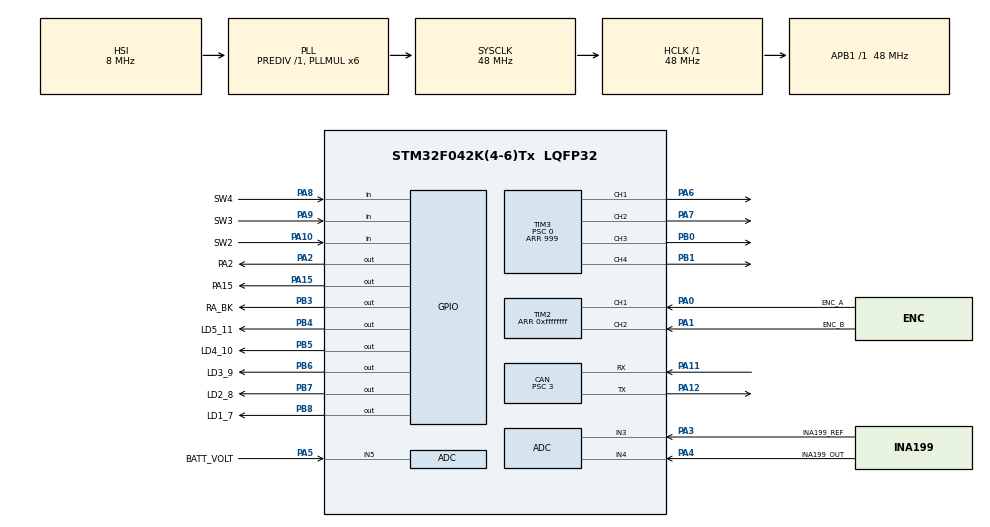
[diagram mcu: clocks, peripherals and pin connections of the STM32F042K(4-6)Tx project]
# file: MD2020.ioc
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ADC.ContinuousConvMode=ENABLE
ADC.DMAContinuousRequests=ENABLE
ADC.EOCSelection=ADC_EOC_SINGLE_CONV
CAN.BS1=CAN_BS1_13TQ
CAN.BS2=CAN_BS2_2TQ
CAN.CalculateTimeQuantum=62.5
CAN.Prescaler=3
CAN.SJW=CAN_SJW_1TQ
Dma.ADC.0.Direction=DMA_PERIPH_TO_MEMORY
Dma.ADC.0.Instance=DMA1_Channel1
Dma.ADC.0.MemDataAlignment=DMA_MDATAALIGN_HALFWORD
Dma.ADC.0.MemInc=DMA_MINC_ENABLE
Dma.ADC.0.Mode=DMA_CIRCULAR
Dma.ADC.0.PeriphDataAlignment=DMA_PDATAALIGN_HALFWORD
Dma.ADC.0.PeriphInc=DMA_PINC_DISABLE
Dma.ADC.0.Priority=DMA_PRIORITY_LOW
Dma.Request0=ADC
FREERTOS.INCLUDE_uxTaskPriorityGet=0
FREERTOS.INCLUDE_vTaskDelayUntil=1
FREERTOS.INCLUDE_vTaskDelete=0
FREERTOS.INCLUDE_vTaskPrioritySet=1
FREERTOS.INCLUDE_vTaskSuspend=0
FREERTOS.MEMORY_ALLOCATION=1
FREERTOS.Tasks01=defaultTask,0,100,StartDefaultTask,Default,NULL,Static,defaultTaskBuffer,defaultTaskControlBlock;Control,3,100,StartControl,Default,NULL,Static,myTask02Buffer,myTask02ControlBlock
FREERTOS.configMAX_TASK_NAME_LEN=12
FREERTOS.configMINIMAL_STACK_SIZE=100
FREERTOS.configTOTAL_HEAP_SIZE=1024
Mcu.Family=STM32F0
Mcu.Name=STM32F042K(4-6)Tx
Mcu.Package=LQFP32
NVIC.DMA1_Channel1_IRQn=true\:3\:0\:false\:false\:true\:true\:false\:true
NVIC.TIM17_IRQn=true\:0\:0\:false\:false\:true\:false\:false\:true
NVIC.TIM3_IRQn=true\:3\:0\:false\:false\:true\:true\:true\:true
NVIC.TimeBase=TIM17_IRQn
NVIC.TimeBaseIP=TIM17
PA0.GPIO_Label=ENC_A
PA0.Signal=S_TIM2_CH1_ETR
PA1.GPIO_Label=ENC_B
PA1.Signal=S_TIM2_CH2
PA10.GPIO_Label=SW2
PA10.GPIO_PuPd=GPIO_PULLUP
PA10.Signal=GPIO_Input
PA11.Mode=Master
PA11.Signal=CAN_RX
PA12.Mode=Master
PA12.Signal=CAN_TX
PA13.Mode=Serial_Wire
PA13.Signal=SYS_SWDIO
PA14.Mode=Serial_Wire
PA14.Signal=SYS_SWCLK
PA15.GPIO_Label=PA15
PA15.Signal=GPIO_Output
PA2.GPIO_Label=PA2
PA2.Signal=GPIO_Output
PA3.GPIO_Label=INA199_REF
PA3.Mode=IN3
PA3.Signal=ADC_IN3
PA4.GPIO_Label=INA199_OUT
PA4.Mode=IN4
PA4.Signal=ADC_IN4
PA5.GPIO_Label=BATT_VOLT
PA5.Mode=IN5
PA5.Signal=ADC_IN5
PA6.Signal=S_TIM3_CH1
PA7.Signal=S_TIM3_CH2
PA8.GPIO_Label=SW4
PA8.GPIO_PuPd=GPIO_PULLUP
PA8.Signal=GPIO_Input
PA9.GPIO_Label=SW3
PA9.GPIO_PuPd=GPIO_PULLUP
PA9.Signal=GPIO_Input
PB0.Signal=S_TIM3_CH3
PB1.Signal=S_TIM3_CH4
PB3.GPIO_Label=RA_BK
PB3.Signal=GPIO_Output
PB4.GPIO_Label=LD5_11
PB4.Signal=GPIO_Output
PB5.GPIO_Label=LD4_10
PB5.Signal=GPIO_Output
PB6.GPIO_Label=LD3_9
PB6.Signal=GPIO_Output
PB7.GPIO_Label=LD2_8
PB7.Signal=GPIO_Output
PB8.GPIO_Label=LD1_7
PB8.Signal=GPIO_Output
ProjectManager.HeapSize=0x200
ProjectManager.StackSize=0x400
ProjectManager.TargetToolchain=STM32CubeIDE
RCC.AHBFreq_Value=48000000
RCC.APB1Freq_Value=48000000
RCC.APB1TimFreq_Value=48000000
RCC.HCLKFreq_Value=48000000
RCC.PLLMUL=RCC_PLL_MUL6
RCC.SYSCLKFreq_VALUE=48000000
RCC.SYSCLKSource=RCC_SYSCLKSOURCE_PLLCLK
SH.S_TIM2_CH1_ETR.0=TIM2_CH1,Encoder_Interface
SH.S_TIM2_CH2.0=TIM2_CH2,Encoder_Interface
SH.S_TIM3_CH1.0=TIM3_CH1,PWM Generation1 CH1
SH.S_TIM3_CH2.0=TIM3_CH2,PWM Generation2 CH2
SH.S_TIM3_CH3.0=TIM3_CH3,PWM Generation3 CH3
SH.S_TIM3_CH4.0=TIM3_CH4,PWM Generation4 CH4
TIM2.EncoderMode=TIM_ENCODERMODE_TI12
TIM2.IC1Filter=3
TIM2.IC2Filter=3
TIM2.Period=0xffffffff
TIM3.AutoReloadPreload=TIM_AUTORELOAD_PRELOAD_ENABLE
TIM3.Channel-PWM\ Generation1\ CH1=TIM_CHANNEL_1
TIM3.Channel-PWM\ Generation2\ CH2=TIM_CHANNEL_2
TIM3.Channel-PWM\ Generation3\ CH3=TIM_CHANNEL_3
TIM3.Channel-PWM\ Generation4\ CH4=TIM_CHANNEL_4
TIM3.CounterMode=TIM_COUNTERMODE_UP
TIM3.OCFastMode_PWM-PWM\ Generation1\ CH1=TIM_OCFAST_ENABLE
TIM3.OCFastMode_PWM-PWM\ Generation2\ CH2=TIM_OCFAST_ENABLE
TIM3.OCFastMode_PWM-PWM\ Generation3\ CH3=TIM_OCFAST_ENABLE
TIM3.OCFastMode_PWM-PWM\ Generation4\ CH4=TIM_OCFAST_ENABLE
TIM3.Period=999
TIM3.Prescaler=0
VP_FREERTOS_VS_CMSIS_V1.Mode=CMSIS_V1
VP_SYS_VS_tim17.Mode=TIM17
VP_TIM3_VS_ClockSourceINT.Mode=Internal
board=custom

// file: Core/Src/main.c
/* USER CODE BEGIN Header */
/**
 ******************************************************************************
 * @file           : main.c
 * @brief          : Main program body
 ******************************************************************************
 * @attention
 *
 * <h2><center>&copy; Copyright (c) 2020 STMicroelectronics.
 * All rights reserved.</center></h2>
 *
 * This software component is licensed by ST under BSD 3-Clause license,
 * the "License"; You may not use this file except in compliance with the
 * License. You may obtain a copy of the License at:
 *                        opensource.org/licenses/BSD-3-Clause
 *
 ******************************************************************************
 */
/* USER CODE END Header */

#include "main.h"
#include "cmsis_os.h"
#include "adc.h"
#include "can.h"
#include "dma.h"
#include "tim.h"
#include "gpio.h"

void SystemClock_Config(void);
void MX_FREERTOS_Init(void);

int main(void)
{

  /* MCU Configuration--------------------------------------------------------*/

  /* Reset of all peripherals, Initializes the Flash interface and the Systick. */
  HAL_Init();

  /* Configure the system clock */
  SystemClock_Config();

  /* Initialize all configured peripherals */
  MX_GPIO_Init();
  MX_DMA_Init();
  MX_ADC_Init();
  MX_CAN_Init();
  MX_TIM2_Init();
  MX_TIM3_Init();

  /* Call init function for freertos objects (in freertos.c) */
  MX_FREERTOS_Init();
  /* Start scheduler */
  osKernelStart();

  /* We should never get here as control is now taken by the scheduler */
  /* Infinite loop */
	while (1) {

	}
}

void SystemClock_Config(void)
{
  RCC_OscInitTypeDef RCC_OscInitStruct = {0};
  RCC_ClkInitTypeDef RCC_ClkInitStruct = {0};

  /** Initializes the CPU, AHB and APB busses clocks
  */
  RCC_OscInitStruct.OscillatorType = RCC_OSCILLATORTYPE_HSI|RCC_OSCILLATORTYPE_HSI14;
  RCC_OscInitStruct.HSIState = RCC_HSI_ON;
  RCC_OscInitStruct.HSI14State = RCC_HSI14_ON;
  RCC_OscInitStruct.HSICalibrationValue = RCC_HSICALIBRATION_DEFAULT;
  RCC_OscInitStruct.HSI14CalibrationValue = 16;
  RCC_OscInitStruct.PLL.PLLState = RCC_PLL_ON;
  RCC_OscInitStruct.PLL.PLLSource = RCC_PLLSOURCE_HSI;
  RCC_OscInitStruct.PLL.PLLMUL = RCC_PLL_MUL6;
  RCC_OscInitStruct.PLL.PREDIV = RCC_PREDIV_DIV1;
  if (HAL_RCC_OscConfig(&RCC_OscInitStruct) != HAL_OK)
  {
    Error_Handler();
  }
  /** Initializes the CPU, AHB and APB busses clocks
  */
  RCC_ClkInitStruct.ClockType = RCC_CLOCKTYPE_HCLK|RCC_CLOCKTYPE_SYSCLK
                              |RCC_CLOCKTYPE_PCLK1;
  RCC_ClkInitStruct.SYSCLKSource = RCC_SYSCLKSOURCE_PLLCLK;
  RCC_ClkInitStruct.AHBCLKDivider = RCC_SYSCLK_DIV1;
  RCC_ClkInitStruct.APB1CLKDivider = RCC_HCLK_DIV1;

  if (HAL_RCC_ClockConfig(&RCC_ClkInitStruct, FLASH_LATENCY_1) != HAL_OK)
  {
    Error_Handler();
  }
}

 /**
  * @brief  Period elapsed callback in non blocking mode
  * @note   This function is called  when TIM17 interrupt took place, inside
  * HAL_TIM_IRQHandler(). It makes a direct call to HAL_IncTick() to increment
  * a global variable "uwTick" used as application time base.
  * @param  htim : TIM handle
  * @retval None
  */
void HAL_TIM_PeriodElapsedCallback(TIM_HandleTypeDef *htim)
{
  if (htim->Instance == TIM17) {
    HAL_IncTick();
  }
}

void Error_Handler(void)
{
}

/************************ (C) COPYRIGHT STMicroelectronics *****END OF FILE****/

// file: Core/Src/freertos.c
/* USER CODE BEGIN Header */
/**
 ******************************************************************************
 * File Name          : freertos.c
 * Description        : Code for freertos applications
 ******************************************************************************
 * @attention
 *
 * <h2><center>&copy; Copyright (c) 2020 STMicroelectronics.
 * All rights reserved.</center></h2>
 *
 * This software component is licensed by ST under Ultimate Liberty license
 * SLA0044, the "License"; You may not use this file except in compliance with
 * the License. You may obtain a copy of the License at:
 *                             www.st.com/SLA0044
 *
 ******************************************************************************
 */
/* USER CODE END Header */

#include "FreeRTOS.h"
#include "task.h"
#include "main.h"
#include "cmsis_os.h"

/* USER CODE BEGIN Includes */
#include "tim.h"
#include "gpio.h"
#include "math.h"
#include "control.h"
/* USER CODE END Includes */

osThreadId defaultTaskHandle;
uint32_t defaultTaskBuffer[ 100 ];
osStaticThreadDef_t defaultTaskControlBlock;
osThreadId ControlHandle;
uint32_t myTask02Buffer[ 100 ];
osStaticThreadDef_t myTask02ControlBlock;

void StartDefaultTask(void const * argument);
void StartControl(void const * argument);

void MX_FREERTOS_Init(void); /* (MISRA C 2004 rule 8.1) */

/* GetIdleTaskMemory prototype (linked to static allocation support) */
void vApplicationGetIdleTaskMemory( StaticTask_t **ppxIdleTaskTCBBuffer, StackType_t **ppxIdleTaskStackBuffer, uint32_t *pulIdleTaskStackSize );

/* USER CODE BEGIN GET_IDLE_TASK_MEMORY */
static StaticTask_t xIdleTaskTCBBuffer;
static StackType_t xIdleStack[configMINIMAL_STACK_SIZE];

void vApplicationGetIdleTaskMemory(StaticTask_t **ppxIdleTaskTCBBuffer,
		StackType_t **ppxIdleTaskStackBuffer, uint32_t *pulIdleTaskStackSize) {
	*ppxIdleTaskTCBBuffer = &xIdleTaskTCBBuffer;
	*ppxIdleTaskStackBuffer = &xIdleStack[0];
	*pulIdleTaskStackSize = configMINIMAL_STACK_SIZE;
	/* place for user code */
}
/* USER CODE END GET_IDLE_TASK_MEMORY */

void MX_FREERTOS_Init(void) {

  /* Create the thread(s) */
  /* definition and creation of defaultTask */
  osThreadStaticDef(defaultTask, StartDefaultTask, osPriorityNormal, 0, 100, defaultTaskBuffer, &defaultTaskControlBlock);
  defaultTaskHandle = osThreadCreate(osThread(defaultTask), NULL);

  /* definition and creation of Control */
  osThreadStaticDef(Control, StartControl, osPriorityRealtime, 0, 100, myTask02Buffer, &myTask02ControlBlock);
  ControlHandle = osThreadCreate(osThread(Control), NULL);

}

void StartDefaultTask(void const * argument)
{
  /* USER CODE BEGIN StartDefaultTask */
	TickType_t xPreviousWakeTime = xTaskGetTickCount();
	/* Infinite loop */
	for (;;) {
		vTaskDelayUntil(&xPreviousWakeTime, 100); //10k/100=100Hz
		LED_Go2Go(get_vel_cmd()/20.0);
//		osDelay(10);
	}
  /* USER CODE END StartDefaultTask */
}

void StartControl(void const * argument)
{
  /* USER CODE BEGIN StartControl */
	TickType_t pxPreviousWakeTime = xTaskGetTickCount();
	Enc_Start(); //init encoder
	PWM_Start();
	/* Infinite loop */
	for (;;) {
		vTaskDelayUntil(&pxPreviousWakeTime, 5); //10k/2=5kHz=0.0002s
		control();
	}
  /* USER CODE END StartControl */
}

/************************ (C) COPYRIGHT STMicroelectronics *****END OF FILE****/
